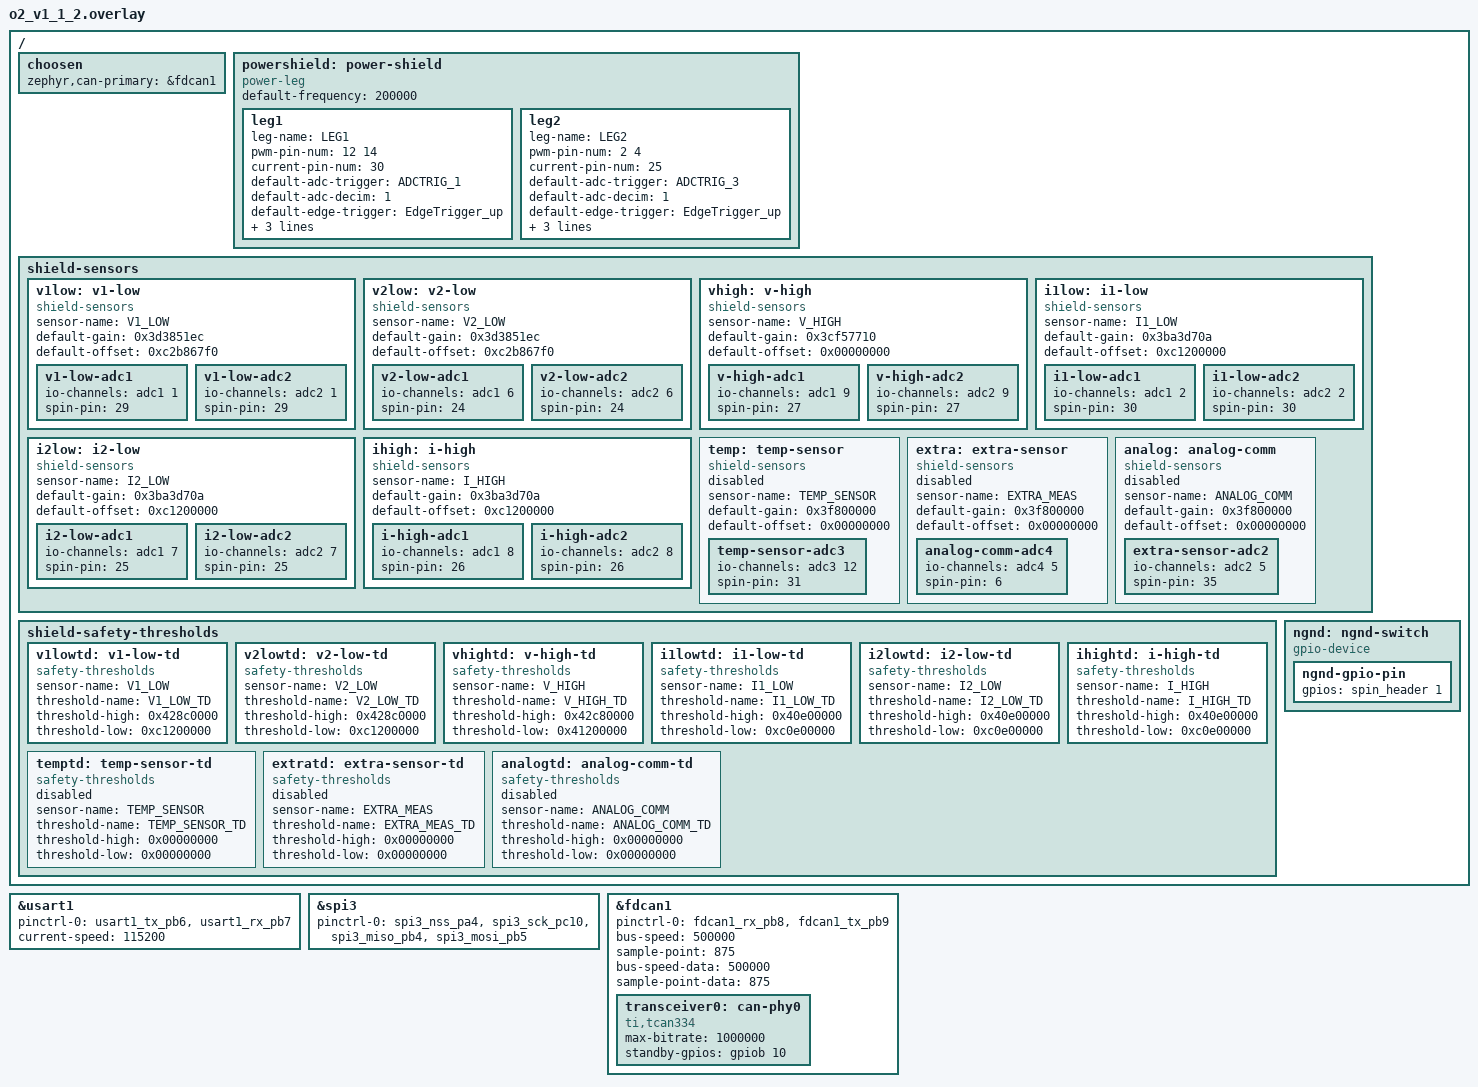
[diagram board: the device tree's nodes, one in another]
/*
 * Copyright (c) 2023-2024 OwnTech.
 *
 * SPDX-License-Identifier: LGPL-2.1
 */

/ {
	choosen{
		zephyr,can-primary = &fdcan1;
	};

	powershield: power-shield{
        compatible = "power-leg";
        default-frequency = <200000>;
        leg1: leg1{
            leg-name = "LEG1";
            pwm-pin-num = <12 14>;
            current-pin-num = <30>;
            default-adc-trigger = "ADCTRIG_1";
            default-adc-decim = <1>;
            default-edge-trigger = "EdgeTrigger_up";
            default-dead-time = <100 100>;
            default-modulation = "UpDwn";
            default-phase-shift = <0>;
			status = "okay";
        };

        leg2: leg2{
            leg-name = "LEG2";
            pwm-pin-num = <2 4>;
            current-pin-num = <25>;
            default-adc-trigger = "ADCTRIG_3";
            default-adc-decim = <1>;
            default-edge-trigger = "EdgeTrigger_up";
            default-dead-time = <100 100>;
            default-modulation = "UpDwn";
            default-phase-shift = <0>;
			status = "okay";
        };
    };

	shield-sensors {
		/* Voltage channels */
		v1low: v1-low {
			compatible = "shield-sensors";
			sensor-name = "V1_LOW";
			default-gain = <0x3d3851ec>;
			default-offset = <0xc2b867f0>;
			v1-low-adc1 {
				io-channels = <&adc1 1>;
				spin-pin = <29>;
			};
			v1-low-adc2 {
				io-channels = <&adc2 1>;
				spin-pin = <29>;
			};
			status = "okay";
		};

		v2low: v2-low {
			compatible = "shield-sensors";
			sensor-name = "V2_LOW";
			default-gain = <0x3d3851ec>;
			default-offset = <0xc2b867f0>;
			v2-low-adc1 {
				io-channels = <&adc1 6>;
				spin-pin = <24>;
			};
			v2-low-adc2 {
				io-channels = <&adc2 6>;
				spin-pin = <24>;
			};
			status = "okay";
		};

		vhigh: v-high {
			compatible = "shield-sensors";
			sensor-name = "V_HIGH";
			default-gain = <0x3cf57710>;
			default-offset = <0x00000000>;
			v-high-adc1 {
				io-channels = <&adc1 9>;
				spin-pin = <27>;
			};
			v-high-adc2 {
				io-channels = <&adc2 9>;
				spin-pin = <27>;
			};
			status = "okay";
		};

		/* Current channels */

		i1low: i1-low {
			compatible = "shield-sensors";
			sensor-name = "I1_LOW";
			default-gain = <0x3ba3d70a>;
			default-offset = <0xc1200000>;
			i1-low-adc1 {
				io-channels = <&adc1 2>;
				spin-pin = <30>;
			};
			i1-low-adc2 {
				io-channels = <&adc2 2>;
				spin-pin = <30>;
			};
			status = "okay";
		};

		i2low: i2-low {
			compatible = "shield-sensors";
			sensor-name = "I2_LOW";
			default-gain = <0x3ba3d70a>;
			default-offset = <0xc1200000>;
			i2-low-adc1 {
				io-channels = <&adc1 7>;
				spin-pin = <25>;
			};
			i2-low-adc2 {
				io-channels = <&adc2 7>;
				spin-pin = <25>;
			};
			status = "okay";
		};

		ihigh: i-high {
			compatible = "shield-sensors";
			sensor-name = "I_HIGH";
			default-gain = <0x3ba3d70a>;
			default-offset = <0xc1200000>;
			i-high-adc1 {
				io-channels = <&adc1 8>;
				spin-pin = <26>;
			};
			i-high-adc2 {
				io-channels = <&adc2 8>;
				spin-pin = <26>;
			};
			status = "okay";
		};

		/* Other channels */

		temp: temp-sensor {
			compatible = "shield-sensors";
			sensor-name = "TEMP_SENSOR";
			default-gain = <0x3f800000>;
			default-offset = <0x00000000>;
			temp-sensor-adc3 {
				io-channels = <&adc3 12>;
				spin-pin = <31>;
			};
			status = "disabled";
		};

		extra: extra-sensor {
			compatible = "shield-sensors";
			sensor-name = "EXTRA_MEAS";
			default-gain = <0x3f800000>;
			default-offset = <0x00000000>;
			analog-comm-adc4 {
				io-channels = <&adc4 5>;
				spin-pin = <6>;
			};
			status = "disabled";
		};

		analog: analog-comm {
			compatible = "shield-sensors";
			sensor-name = "ANALOG_COMM";
			default-gain = <0x3f800000>;
			default-offset = <0x00000000>;
			extra-sensor-adc2 {
				io-channels = <&adc2 5>;
				spin-pin = <35>;
			};
			status = "disabled";
		};
	};

	shield-safety-thresholds {

		/* Voltage thresholds */

		v1lowtd: v1-low-td {
			compatible = "safety-thresholds";
			sensor-name = "V1_LOW";
			threshold-name = "V1_LOW_TD";
			threshold-high = <0x428c0000>; /* 70.0 */
			threshold-low = <0xc1200000>; /* -10.0 */
			status = "okay";
		};

		v2lowtd: v2-low-td {
			compatible = "safety-thresholds";
			sensor-name = "V2_LOW";
			threshold-name = "V2_LOW_TD";
			threshold-high = <0x428c0000>; /* 70.0 */
			threshold-low = <0xc1200000>; /* -10.0 */
			status = "okay";
		};

		vhightd: v-high-td {
			compatible = "safety-thresholds";
			sensor-name = "V_HIGH";
			threshold-name = "V_HIGH_TD";
			threshold-high = <0x42c80000>; /* 100.0 */
			threshold-low = <0x41200000>; /* 10.0 */
			status = "okay";
		};

		/* Current thresholds */

		i1lowtd: i1-low-td {
			compatible = "safety-thresholds";
			sensor-name = "I1_LOW";
			threshold-name = "I1_LOW_TD";
			threshold-high = <0x40e00000>; /* 7.0 */
			threshold-low = <0xc0e00000>; /* -7.0 */
			status = "okay";
		};

		i2lowtd: i2-low-td {
			compatible = "safety-thresholds";
			sensor-name = "I2_LOW";
			threshold-name = "I2_LOW_TD";
			threshold-high = <0x40e00000>; /* 7.0 */
			threshold-low = <0xc0e00000>; /* -7.0 */
			status = "okay";
		};

		ihightd: i-high-td {
			compatible = "safety-thresholds";
			sensor-name = "I_HIGH";
			threshold-name = "I_HIGH_TD";
			threshold-high = <0x40e00000>; /* 7.0 */
			threshold-low = <0xc0e00000>; /* -7.0 */
			status = "okay";
		};

		/* Other channels thresholds */

		temptd: temp-sensor-td {
			compatible = "safety-thresholds";
			sensor-name = "TEMP_SENSOR";
			threshold-name = "TEMP_SENSOR_TD";
			threshold-high = <0x00000000>;
			threshold-low = <0x00000000>;
			status = "disabled";
		};

		extratd: extra-sensor-td {
			compatible = "safety-thresholds";
			sensor-name = "EXTRA_MEAS";
			threshold-name = "EXTRA_MEAS_TD";
			threshold-high = <0x00000000>;
			threshold-low = <0x00000000>;
			status = "disabled";
		};

		analogtd: analog-comm-td {
			compatible = "safety-thresholds";
			sensor-name = "ANALOG_COMM";
			threshold-name = "ANALOG_COMM_TD";
			threshold-high = <0x00000000>;
			threshold-low = <0x00000000>;
			status = "disabled";
		};
	};

	ngnd: ngnd-switch {
		compatible = "gpio-device";
		ngnd-gpio-pin {
			gpios = <&spin_header 1 GPIO_ACTIVE_HIGH>;
		};
	};
};

// UART1

&usart1 {
	pinctrl-0 = <&usart1_tx_pb6 &usart1_rx_pb7>;
	pinctrl-names = "default";
	current-speed = <115200>;
	status = "okay";
};

// SPI

&spi3 {
	pinctrl-0 = <&spi3_nss_pa4 &spi3_sck_pc10 &spi3_miso_pb4 &spi3_mosi_pb5>;
	pinctrl-names = "default";
	status = "okay";
};

// CAN

&fdcan1 {
	pinctrl-0 = <&fdcan1_rx_pb8 &fdcan1_tx_pb9>;
	pinctrl-names = "default";
	bus-speed = <500000>;
	sample-point = <875>;
	bus-speed-data = <500000>;
	sample-point-data = <875>;
	status = "okay";
	transceiver0: can-phy0 {
		compatible = "ti,tcan334", "can-transceiver-gpio";
		max-bitrate = <1000000>;
		standby-gpios = <&gpiob 10 GPIO_ACTIVE_HIGH>;
		#phy-cells = <0>;
	};
};
